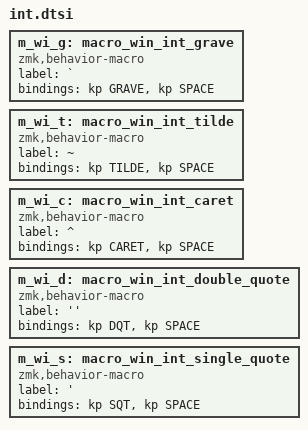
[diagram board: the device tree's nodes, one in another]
m_wi_g: macro_win_int_grave {
    compatible = "zmk,behavior-macro";
    label = "`";
    #binding-cells = <0>;
    bindings =
        <&kp GRAVE &kp SPACE>;
};

m_wi_t: macro_win_int_tilde {
    compatible = "zmk,behavior-macro";
    label = "~";
    #binding-cells = <0>;
    bindings =
        <&kp TILDE &kp SPACE>;
};

m_wi_c: macro_win_int_caret {
    compatible = "zmk,behavior-macro";
    label = "^";
    #binding-cells = <0>;
    bindings =
        <&kp CARET &kp SPACE>;
};

m_wi_d: macro_win_int_double_quote {
    compatible = "zmk,behavior-macro";
    label = "''";
    #binding-cells = <0>;
    bindings =
        <&kp DQT &kp SPACE>;
};

m_wi_s: macro_win_int_single_quote {
    compatible = "zmk,behavior-macro";
    label = "'";
    #binding-cells = <0>;
    bindings =
        <&kp SQT &kp SPACE>;
};
